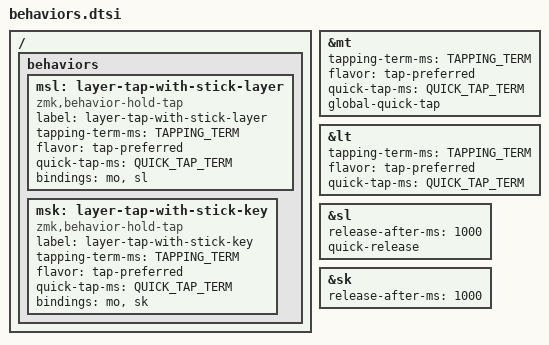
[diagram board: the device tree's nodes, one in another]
/*
*
* Copyright (c) 2022 Rafael Romão
* SPDX-License-Identifier: MIT
*
*/

&mt {
    tapping-term-ms = <TAPPING_TERM>;
    flavor = "tap-preferred";
    quick-tap-ms = <QUICK_TAP_TERM>;
    global-quick-tap;
};

&lt {
    tapping-term-ms = <TAPPING_TERM>;
    flavor = "tap-preferred";
    quick-tap-ms = <QUICK_TAP_TERM>;
};

&sl {
    release-after-ms = <1000>;
    quick-release;
};

&sk {
    release-after-ms = <1000>;
};

/ {
    behaviors {
        msl: layer-tap-with-stick-layer {
            compatible = "zmk,behavior-hold-tap";
            label = "layer-tap-with-stick-layer";
            #binding-cells = <2>;
            tapping-term-ms = <TAPPING_TERM>;
            flavor = "tap-preferred";
            quick-tap-ms = <QUICK_TAP_TERM>;
            bindings = <&mo>, <&sl>;
        };
        msk: layer-tap-with-stick-key {
            compatible = "zmk,behavior-hold-tap";
            label = "layer-tap-with-stick-key";
            #binding-cells = <2>;
            tapping-term-ms = <TAPPING_TERM>;
            flavor = "tap-preferred";
            quick-tap-ms = <QUICK_TAP_TERM>;
            bindings = <&mo>, <&sk>;
        };
    };
};
